# MCXN236 register map
Vendor: nxp.com; File version: 1.0
CPU: CM33 r2p0, little endian, MPU, FPU, VTOR, 3 interrupt priority bits
Registers are 32-bit, read-write, reset 0x0 unless marked. A register's access mark holds for its fields unless they carry their own. Offsets are from the block's base; [hi:lo] are bit positions; {n}, {i} and the like mark numbered series; 'fields as' and 'values as' point back to an identical list.

## SYSCON0 — SYSCON
Base 0x40000000
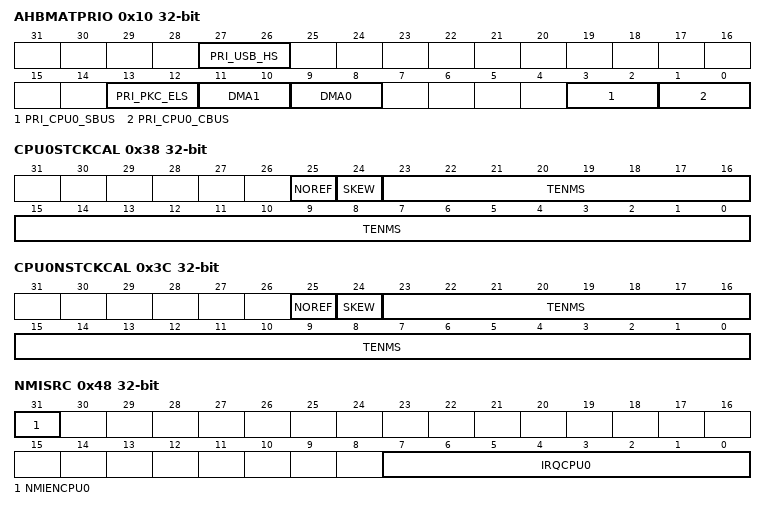
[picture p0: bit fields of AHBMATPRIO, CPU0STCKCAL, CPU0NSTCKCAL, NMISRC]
0x10 AHBMATPRIO — AHB Matrix Priority Control
  [all] fields
    {v}=LEVEL{v} (v=0..3)
  [27:26] PRI_USB_HS — USB-HS bus master priority level
  [13:12] PRI_PKC_ELS — PKC and ELS bus master priority level
  [11:10] DMA1 — DMA1 controller bus master priority level
  [9:8] DMA0 — DMA0 controller bus master priority level
  [3:2] PRI_CPU0_SBUS — CPU0 S-AHB bus master priority level
  [1:0] PRI_CPU0_CBUS — CPU0 C-AHB bus master priority level
0x38 CPU0STCKCAL — Secure CPU0 System Tick Calibration
  [25] NOREF — Whether the device provides a reference clock to the processor.
    0=YES_REF (Reference clock is provided); 1=NO_REF (No reference clock is provided)
  [24] SKEW — Whether the TENMS value is exact.
    0=EXACT (TENMS value is exact); 1=INEXACT (TENMS value is not exact or not given)
  [23:0] TENMS — Reload value for 10 ms (100 Hz) timing, subject to system clock skew errors. If the value reads as zero, the calibration value is not known.
0x3C CPU0NSTCKCAL — Non-Secure CPU0 System Tick Calibration
  [25] NOREF — Indicates whether the device provides a reference clock to the processor.
    values as CPU0STCKCAL.NOREF
  [24] SKEW — Indicates whether the TENMS value is exact.
    values as CPU0STCKCAL.SKEW
  [23:0] TENMS — Reload value for 10 ms (100 Hz) timing, subject to system clock skew errors. If the value reads as zero, the calibration value is not known.
0x48 NMISRC — NMI Source Select
  [31] NMIENCPU0 — Enables the Non-Maskable Interrupt (NMI) source selected by IRQCPU0.
    0=DISABLE; 1=ENABLE
  [7:0] IRQCPU0 — The IRQ number of the interrupt that acts as the Non-Maskable Interrupt (NMI) for CPU0, if enabled by NMIENCPU0.
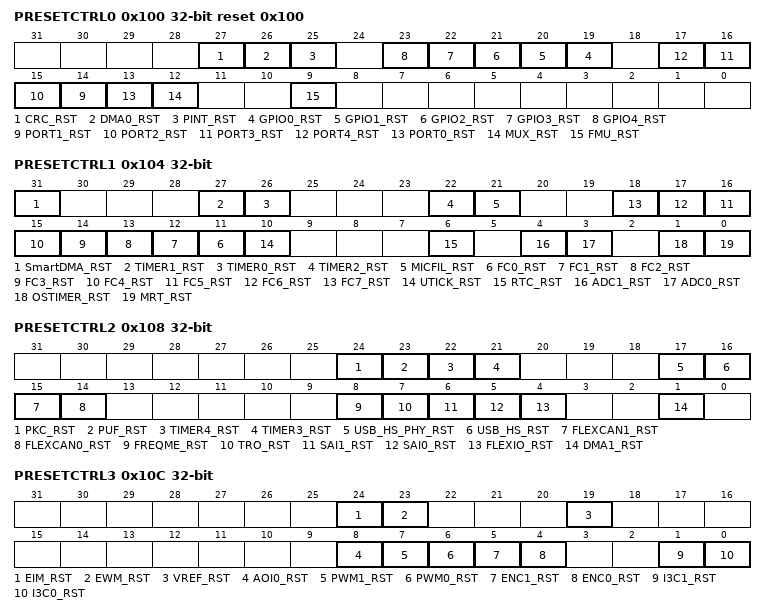
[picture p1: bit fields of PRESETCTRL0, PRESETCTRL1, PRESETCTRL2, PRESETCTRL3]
0x100 PRESETCTRL0 reset 0x100 (reset mask 0xCEFB13FC) — Peripheral Reset Control 0
  [all] fields
    0=RELEASED (Block is not reset); 1=ASSERTED (Block is reset)
  [27] CRC_RST — CRC reset control
  [26] DMA0_RST — DMA0 reset control
  [25] PINT_RST — PINT reset control
  [n+19] GPIO{n}_RST (n=0..4) — GPIO{n} reset control
  [n+13] PORT{n}_RST (n=1..4) — PORT{n} reset control
  [13] PORT0_RST — PORT0 controller reset control
  [12] MUX_RST — INPUTMUX reset control
  [9] FMU_RST — Flash management unit reset control
0x104 PRESETCTRL1 (reset mask 0xAFFFFF3F) — Peripheral Reset Control 1
  [all] fields
    0=RELEASED (Block is not reset); 1=ASSERTED (Block is reset)
  [31] SmartDMA_RST — SmartDMA reset control
  [27] TIMER1_RST — CTIMER1 reset control
  [26] TIMER0_RST — CTIMER0 reset control
  [22] TIMER2_RST — CTIMER2 reset control
  [21] MICFIL_RST — MICFIL reset control
  [n+11] FC{n}_RST (n=0..7) — LP_FLEXCOMM{n} reset control
  [10] UTICK_RST — UTICK reset control
  [6] RTC_RST — RTC reset control
  [4] ADC1_RST — ADC1 reset control
  [3] ADC0_RST — ADC0 reset control
  [1] OSTIMER_RST — OS Event Timer reset control
  [0] MRT_RST — MRT reset control
0x108 PRESETCTRL2 — Peripheral Reset Control 2
  [all] fields
    0=RELEASED (Block is not reset); 1=ASSERTED (Block is reset)
  [24] PKC_RST — PKC reset control
  [23] PUF_RST — PUF reset control
  [22] TIMER4_RST — CTIMER4 reset control
  [21] TIMER3_RST — CTIMER3 reset control
  [17] USB_HS_PHY_RST — USB HS PHY reset control
  [16] USB_HS_RST — USB HS reset control
  [15] FLEXCAN1_RST — CAN1 reset control
  [14] FLEXCAN0_RST — CAN0 reset control
  [8] FREQME_RST — FREQME reset control
  [7] TRO_RST — TRO reset control
  [6] SAI1_RST — SAI1 reset control
  [5] SAI0_RST — SAI0 reset control
  [4] FLEXIO_RST — FLEXIO reset control
  [1] DMA1_RST — DMA1 reset control
0x10C PRESETCTRL3 — Peripheral Reset Control 3
  [all] fields
    0=RELEASED (Block is not reset); 1=ASSERTED (Block is reset)
  [24] EIM_RST — EIM reset control
  [23] EWM_RST — EWM reset control
  [19] VREF_RST — VREF reset control
  [8] AOI0_RST — AOI0 reset control
  [7] PWM1_RST — PWM1 reset control
  [6] PWM0_RST — PWM0 reset control
  [5] ENC1_RST — ENC1 reset control
  [4] ENC0_RST — ENC0 reset control
  [1] I3C1_RST — I3C1 reset control
  [0] I3C0_RST — I3C0 reset control
{0x120+4i} PRESETCTRLSET[{i}] (i=0..3) wo — Peripheral Reset Control Set
  [31:0] DATA — Data array value, refer to corresponding position in PRESETCTRLn.
{0x140+4i} PRESETCTRLCLR[{i}] (i=0..3) wo — Peripheral Reset Control Clear
  fields as PRESETCTRLSET[0]
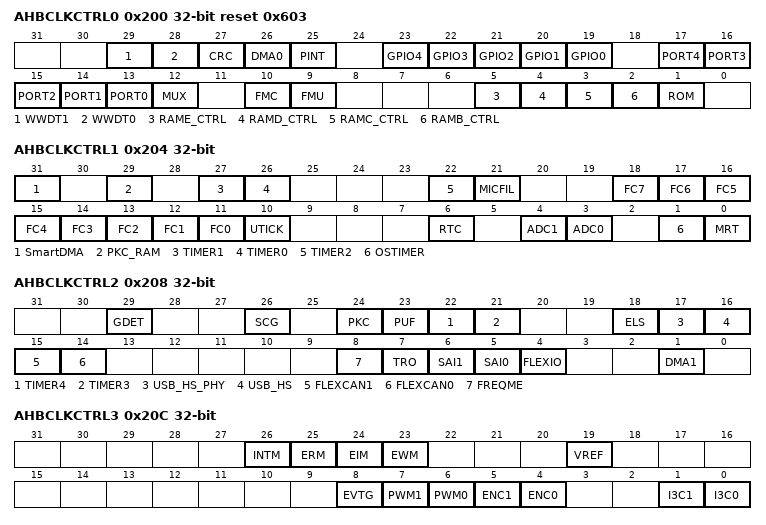
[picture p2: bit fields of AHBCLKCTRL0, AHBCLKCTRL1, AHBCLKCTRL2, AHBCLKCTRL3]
0x200 AHBCLKCTRL0 reset 0x603 — AHB Clock Control 0
  [all] fields
    0=DISABLE (Disables clock); 1=ENABLE (Enables clock)
  [29] WWDT1 — Enables the clock for WWDT1
  [28] WWDT0 — Enables the clock for WWDT0
  [27] CRC — Enables the clock for CRC
  [26] DMA0 — Enables the clock for DMA0
  [25] PINT — Enables the clock for PINT
  [n+19] GPIO{n} (n=0..4) — Enables the clock for GPIO{n}
  [n+13] PORT{n} (n=1..4) — Enables the clock for PORT{n}
  [13] PORT0 — Enables the clock for PORT0 controller
  [12] MUX — Enables the clock for INPUTMUX
  [10] FMC — Enables the clock for the Flash Memory Controller
  [9] FMU — Enables the clock for the Flash Management Unit
  [5] RAME_CTRL — Enables the clock for the RAME Controller
  [4] RAMD_CTRL — Enables the clock for the RAMD Controller
  [3] RAMC_CTRL — Enables the clock for the RAMC Controller
  [2] RAMB_CTRL — Enables the clock for the RAMB Controller
  [1] ROM — Enables the clock for the ROM
0x204 AHBCLKCTRL1 — AHB Clock Control 1
  [all] fields
    0=DISABLE (Disables clock); 1=ENABLE (Enables clock)
  [31] SmartDMA — Enables the clock for SmartDMA
  [29] PKC_RAM — Enables the clock for PKC RAM
  [27] TIMER1 — Enables the clock for CTIMER1
  [26] TIMER0 — Enables the clock for CTIMER0
  [22] TIMER2 — Enables the clock for CTIMER2
  [21] MICFIL — Enables the clock for MICFIL
  [n+11] FC{n} (n=0..7) — Enables the clock for LP_FLEXCOMM{n}
  [10] UTICK — Enables the clock for UTICK
  [6] RTC — Enables the clock for RTC
  [4] ADC1 — Enables the clock for ADC1
  [3] ADC0 — Enables the clock for ADC0
  [1] OSTIMER — Enables the clock for the OS Event Timer
  [0] MRT — Enables the clock for MRT
0x208 AHBCLKCTRL2 — AHB Clock Control 2
  [29] GDET — Enables the clock for GDET0 and GDET1
    0=DISABLE (Disables clock); 1=ENABLE (Enables clock)
  [26] SCG — Enables the clock for SCG
    0=DISABLE (Disables clock); 1=ENABLE (Enables clock)
  [24] PKC — Enables the clock for PKC
    0=DISABLE (Disables clock); 1=ENABLE (Enables clock)
  [23] PUF — Enables the clock for PUF
    0=DISABLE (Disables clock); 1=ENABLE (Enables clock)
  [22] TIMER4 — Enables the clock for CTIMER4
    0=DISABLE (Disables clock); 1=ENABLE (Enables clock)
  [21] TIMER3 — Enables the clock for CTIMER3
    0=DISABLE (Disables clock); 1=ENABLE (Enables clock)
  [18] ELS — Enables the clock for ELS
    0=DISABLE (Disables clock); 1=ENABLE (Enables clock)
  [17] USB_HS_PHY — Enables the clock for USB HS PHY
    0=DISABLE (Disables clock); 1=ENABLE (Enables clock)
  [16] USB_HS — Enables the clock for USB HS
    0=DISABLE (Disables clock); 1=ENABLE (Enables clock)
  [15] FLEXCAN1 — Enables the clock for FLEXCAN1
    0=DISABLE (Disables clock); 1=ENABLE (Enables clock)
  [14] FLEXCAN0 — Enables the clock for FLEXCAN0
    0=DISABLE (Disables clock); 1=ENABLE (Enables clock)
  [8] FREQME — Enables the clock for the Frequency meter
    0=DISABLE (Disables clock); 1=ENABLE (Enables clock)
  [7] TRO — Enables the clock for TRO
    0=DISABLE (Disables clock); 1=ENABLE (Enables clock)
  [6] SAI1 — Enables the clock for SAI1
    0=DISABLE (Disables clock); 1=ENABLE (Enables clock)
  [5] SAI0 — Enables the clock for SAI0
    0=DISABLE (Disables clock); 1=ENABLE (Enables clock)
  [4] FLEXIO — Enables the clock for Flexio
    0=DISABLE (Disables clock); 1=ENABLE (Enable clock)
  [1] DMA1 — Enables the clock for DMA1
    0=DISABLE (Disables clock); 1=ENABLE (Enables clock)
0x20C AHBCLKCTRL3 — AHB Clock Control 3
  [all] fields
    0=DISABLE (Disables clock); 1=ENABLE (Enables clock)
  [26] INTM — Enables the clock for INTM
  [25] ERM — Enables the clock for ERM
  [24] EIM — Enables the clock for EIM
  [23] EWM — Enables the clock for EWM
  [19] VREF — Enables the clock for VREF
  [8] EVTG — Enables the clock for EVTG
  [7] PWM1 — Enables the clock for PWM1
  [6] PWM0 — Enables the clock for PWM0
  [5] ENC1 — Enables the clock for ENC1
  [4] ENC0 — Enables the clock for ENC0
  [1] I3C1 — Enables the clock for I3C1
  [0] I3C0 — Enables the clock for I3C0
{0x220+4i} AHBCLKCTRLSET[{i}] (i=0..3) wo — AHB Clock Control Set
  [31:0] DATA — Data array value
{0x240+4i} AHBCLKCTRLCLR[{i}] (i=0..3) wo — AHB Clock Control Clear
  [31:0] DATA — Data array value
0x260 SYSTICKCLKSEL0 reset 0x7 — CPU0 System Tick Timer Source Select
  [2:0] SEL — Selects the System Tick Timer for CPU0 source
    0=ENUM_0x0 (SYSTICKCLKDIV0 output); 1=ENUM_0x1 (Clk 1 MHz clock); 2=ENUM_0x2 (LP Oscillator clock); {v}=ENUM_{0x0+v} (No clock) (v=3..7)
0x268 TRACECLKSEL reset 0x7 — Trace Clock Source Select
  [2:0] SEL — Selects the trace clock source.
    0=ENUM_0x0 (TRACECLKDIV output); 1=ENUM_0x1 (Clk 1 MHz clock); 2=ENUM_0x2 (LP Oscillator clock); {v}=ENUM_{0x0+v} (No clock) (v=3..7)
{0x26C+4i} CTIMERCLKSEL[{i}] (i=0..4) reset 0xF — CTIMER Clock Source Select
  [3:0] SEL — Selects the CTIMER clock source.
    0=ENUM_0x0 (FRO_1M clock); 1=ENUM_0x1 (PLL0 clock); 2=ENUM_0x2 (PLL1_clk0 clock); 3=ENUM_0x3 (FRO_HF clock); 4=ENUM_0x4 (FRO 12MHz clock); 5=ENUM_0x5 (SAI0 MCLK IN clock); 6=ENUM_0x6 (LP Oscillator clock); 7=ENUM_0x7 (No clock); 8=ENUM_0x8 (SAI1 MCLK IN clock); 9=ENUM_0x9 (SAI0 TX_BCLK clock); 10=ENUM_0xA (SAI0 RX_BCLK clock); 11=ENUM_0xB (SAI1 TX_BCLK clock); 12=ENUM_0xC (SAI1 RX_BCLK clock); 13=ENUM_0xD (No clock); 14=ENUM_0xE (No clock); 15=ENUM_0xF (No clock)
0x288 CLKOUTSEL reset 0xF — CLKOUT Clock Source Select
  [3:0] SEL — Selects the CLKOUT clock source.
    0=ENUM_0x0 (Main clock (main_clk)); 1=ENUM_0x1 (PLL0 clock (pll0_clk)); 2=ENUM_0x2 (CLKIN clock (clk_in)); 3=ENUM_0x3 (FRO_HF clock (fro_hf)); 4=ENUM_0x4 (FRO 12 MHz clock (fro_12m)); 5=ENUM_0x5 (PLL1_clk0 clock (pll1_clk)); 6=ENUM_0x6 (LP Oscillator clock (lp_osc)); 7=ENUM_0x7 (USB PLL clock (usb_pll_clk)); {v}=ENUM_{0x0+v} (No clock) (v=8..15)
0x2A4 ADC0CLKSEL reset 0x7 — ADC0 Clock Source Select
  [2:0] SEL — Selects the ADC0 clock source.
    0=ENUM_0x0 (No clock); 1=ENUM_0x1 (PLL0 clock); 2=ENUM_0x2 (FRO_HF clock); 3=ENUM_0x3 (FRO 12 MHz clock); 4=ENUM_0x4 (Clk_in); 5=ENUM_0x5 (PLL1_clk0 clock); 6=ENUM_0x6 (USB PLL clock); 7=ENUM_0x7 (No clock)
{0x2B0+4i} FCCLKSEL[{i}] (i=0..7) reset 0x7 — LP_FLEXCOMM Clock Source Select for Fractional Rate Divider
  [2:0] SEL — Selects the LP_FLEXCOMM clock source for Fractional Rate Divider.
    0=ENUM_0x0 (No clock); 1=ENUM_0x1 (PLL divided clock); 2=ENUM_0x2 (FRO 12 MHz clock); 3=ENUM_0x3 (fro_hf_div clock); 4=ENUM_0x4 (CLK_1MHz clock); 5=ENUM_0x5 (USB PLL clock); 6=ENUM_0x6 (LP Oscillator clock); 7=ENUM_0x7 (No clock)
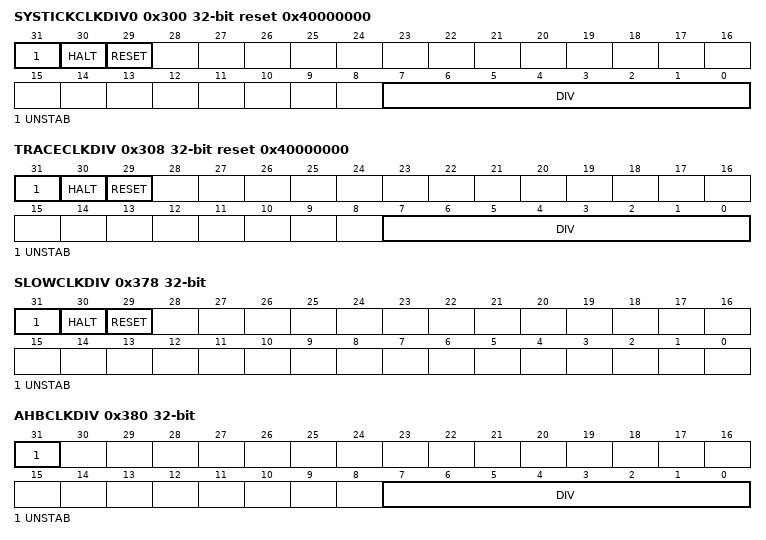
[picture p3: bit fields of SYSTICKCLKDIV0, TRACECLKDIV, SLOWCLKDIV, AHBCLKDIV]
0x300 SYSTICKCLKDIV0 reset 0x40000000 — CPU0 System Tick Timer Divider
  [31] UNSTAB ro — Divider status flag
    0=STABLE (Divider clock is stable); 1=ONGOING (Clock frequency is not stable)
  [30] HALT — Halts the divider counter
    0=RUN (Divider clock is running); 1=HALT (Divider clock is stopped)
  [29] RESET — Resets the divider counter
    0=RELEASED (Divider is not reset); 1=ASSERTED (Divider is reset.)
  [7:0] DIV — Clock divider value
0x308 TRACECLKDIV reset 0x40000000 — TRACE Clock Divider
  [31] UNSTAB ro — Divider status flag
    values as SYSTICKCLKDIV0.UNSTAB
  [30] HALT — Halts the divider counter
    values as SYSTICKCLKDIV0.HALT
  [29] RESET — Resets the divider counter
    0=RELEASED (Divider is not reset); 1=ASSERTED (Divider is reset)
  [7:0] DIV — Clock divider value
0x378 SLOWCLKDIV — SLOW_CLK Clock Divider
  [31] UNSTAB ro — Divider status flag
    values as SYSTICKCLKDIV0.UNSTAB
  [30] HALT — Halts the divider counter
    values as SYSTICKCLKDIV0.HALT
  [29] RESET — Resets the divider counter
    values as TRACECLKDIV.RESET
0x380 AHBCLKDIV — System Clock Divider
  [31] UNSTAB ro — Divider status flag
    values as SYSTICKCLKDIV0.UNSTAB
  [7:0] DIV — Clock divider value
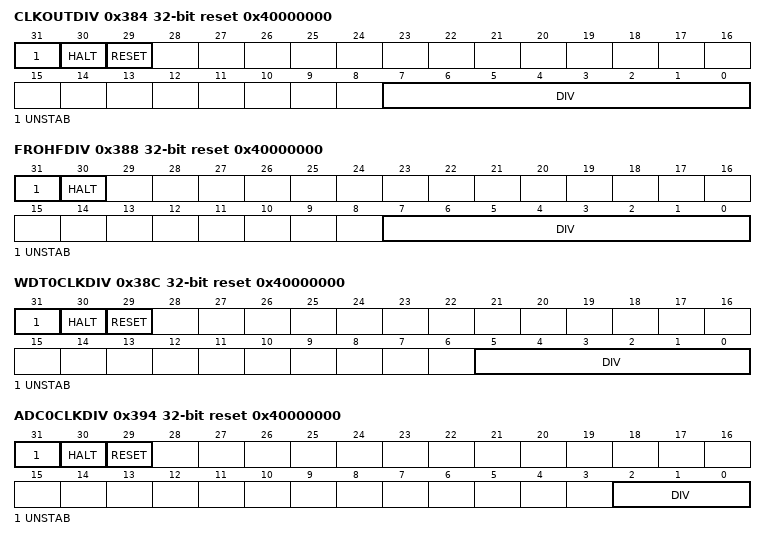
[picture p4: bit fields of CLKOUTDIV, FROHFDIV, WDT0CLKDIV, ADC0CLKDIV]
0x384 CLKOUTDIV reset 0x40000000 — CLKOUT Clock Divider
  fields as TRACECLKDIV
0x388 FROHFDIV reset 0x40000000 — FRO_HF_DIV Clock Divider
  [31] UNSTAB ro — Divider status flag
    values as SYSTICKCLKDIV0.UNSTAB
  [30] HALT ro — Halts the divider counter
    0=RUN (Divider clock is running, this bit is set to 0 when the register is written.); 1=HALT (Divider clock is stopped)
  [7:0] DIV — Clock divider value
0x38C WDT0CLKDIV reset 0x40000000 — WDT0 Clock Divider
  [31] UNSTAB ro — Divider status flag
    values as SYSTICKCLKDIV0.UNSTAB
  [30] HALT — Halts the divider counter
    values as SYSTICKCLKDIV0.HALT
  [29] RESET — Resets the divider counter
    values as TRACECLKDIV.RESET
  [5:0] DIV — Clock divider value
0x394 ADC0CLKDIV reset 0x40000000 — ADC0 Clock Divider
  [31] UNSTAB ro — Divider status flag
    values as SYSTICKCLKDIV0.UNSTAB
  [30] HALT — Halts the divider counter
    values as SYSTICKCLKDIV0.HALT
  [29] RESET — Resets the divider counter
    values as TRACECLKDIV.RESET
  [2:0] DIV — Clock divider value
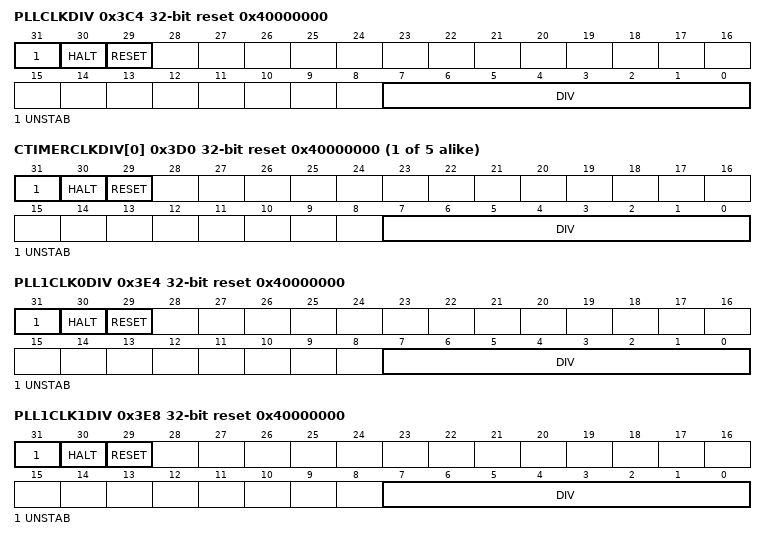
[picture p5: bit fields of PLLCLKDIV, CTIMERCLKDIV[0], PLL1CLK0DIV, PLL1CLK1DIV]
0x3C4 PLLCLKDIV reset 0x40000000 — PLL Clock Divider
  fields as TRACECLKDIV
{0x3D0+4i} CTIMERCLKDIV[{i}] (i=0..4) reset 0x40000000 — CTimer Clock Divider
  [31] UNSTAB — Divider status flag
    0=ENABLE (Stable divider clock); 1=DISABLE (Unstable clock frequency)
  [30] HALT — Halts the divider counter
    0=ENABLE (Divider clock is running); 1=DISABLE (Divider clock has stopped)
  [29] RESET — Resets the divider counter
    0=DISABLE (Divider is not reset); 1=ENABLE (Divider is reset)
  [7:0] DIV — Clock divider value
0x3E4 PLL1CLK0DIV reset 0x40000000 — PLL1 Clock 0 Divider
  fields as TRACECLKDIV
0x3E8 PLL1CLK1DIV reset 0x40000000 — PLL1 Clock 1 Divider
  fields as TRACECLKDIV
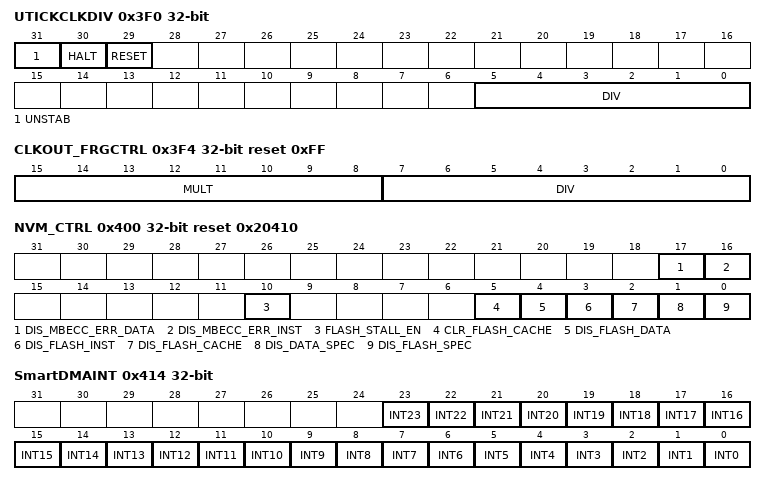
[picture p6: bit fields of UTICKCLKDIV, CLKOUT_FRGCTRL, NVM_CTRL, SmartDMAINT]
0x3F0 UTICKCLKDIV — UTICK Clock Divider
  fields as WDT0CLKDIV
0x3F4 CLKOUT_FRGCTRL reset 0xFF — CLKOUT FRG Control
  [15:8] MULT — Numerator value
  [7:0] DIV — Divider value
0x3FC CLKUNLOCK — Clock Configuration Unlock
  [0] UNLOCK — Controls clock configuration registers access (for example, xxxDIV, xxxSEL)
    0=ENABLE (Updates are allowed to all clock configuration registers); 1=FREEZE (Freezes all clock configuration registers update)
0x400 NVM_CTRL reset 0x20410 — NVM Control
  [17] DIS_MBECC_ERR_DATA — Bus error on data multi-bit ECC error control
    0=ENABLE (Enables bus error on multi-bit ECC error for data); 1=DISABLE (Disables bus error on multi-bit ECC error for data)
  [16] DIS_MBECC_ERR_INST — Bus error on instruction multi-bit ECC error control
    0=ENABLE (Enables bus error on multi-bit ECC error for instruction); 1=DISABLE (Disables bus error on multi-bit ECC error for instruction)
  [10] FLASH_STALL_EN — FLASH stall on busy control
    0=ENABLE (No stall on FLASH busy); 1=DISABLE (Stall on FLASH busy)
  [5] CLR_FLASH_CACHE — Clear flash cache control
    0=ENABLE (No clear flash cache); 1=DISABLE (Clears flash cache)
  [4] DIS_FLASH_DATA — Flash data cache control
    0=ENABLE (Enables flash data cache when DIS_FLASH_CACHE=0); 1=DISABLE (Disables flash data cache)
  [3] DIS_FLASH_INST — Flash instruction cache control
    0=ENABLE (Enables flash instruction cache when DIS_FLASH_CACHE=0); 1=DISABLE (Disables flash instruction cache)
  [2] DIS_FLASH_CACHE — Flash cache control
    0=ENABLE (Enables flash cache); 1=DISABLE (Disables flash cache)
  [1] DIS_DATA_SPEC — Flash data speculation control
    0=ENABLE (Enables data speculation); 1=DISABLE (Disables data speculation)
  [0] DIS_FLASH_SPEC — Flash speculation control
    0=ENABLE (Enables flash speculation); 1=DISABLE (Disables flash speculation)
0x404 ROMCR — ROM Wait State
  [0] ROM_WAIT — ROM waiting Arm core and other masters for one cycle
    0=DISABLE (Disabled); 1=Enabled
0x414 SmartDMAINT — SmartDMA Interrupt Hijack
  [all] fields
    0=DISABLE; 1=ENABLE
  [23] INT23 — SmartDMA hijack NVIC IRQ77
  [22] INT22 — SmartDMA hijack NVIC IRQ67
  [21] INT21 — SmartDMA hijack NVIC IRQ66
  [20] INT20 — SmartDMA hijack NVIC IRQ51
  [19] INT19 — SmartDMA hijack NVIC IRQ50
  [18] INT18 — SmartDMA hijack NVIC IRQ47
  [17] INT17 — SmartDMA hijack NVIC IRQ45
  [n] INT{n} (n=3..16) — SmartDMA hijack NVIC IRQ{n+26}
  [2] INT2 — SmartDMA hijack NVIC IRQ18
  [1] INT1 — SmartDMA hijack NVIC IRQ17
  [0] INT0 — SmartDMA hijack NVIC IRQ1
0x464 ADC1CLKSEL reset 0x7 — ADC1 Clock Source Select
  [2:0] SEL — Selects the ADC1 clock source
    0=ENUM_0x0 (No clock); 1=ENUM_0x1 (PLL0 clock); 2=ENUM_0x2 (FRO_HF clock); 3=ENUM_0x3 (FRO 12 MHz clock); 4=ENUM_0x4 (Clk_in clock); 5=ENUM_0x5 (PLL1_clk0 clock); 6=ENUM_0x6 (USB PLL clock); 7=ENUM_0x7 (No clock)
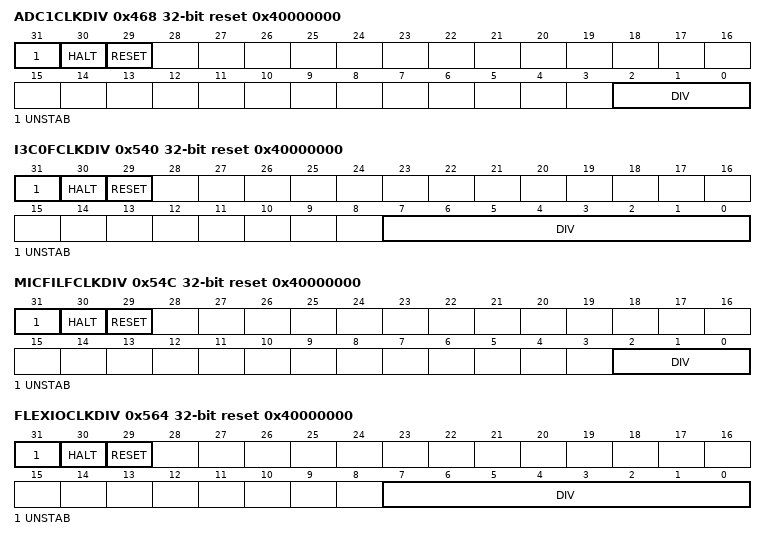
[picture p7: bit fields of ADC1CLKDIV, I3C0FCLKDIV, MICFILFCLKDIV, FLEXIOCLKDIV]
0x468 ADC1CLKDIV reset 0x40000000 — ADC1 Clock Divider
  fields as ADC0CLKDIV
0x470 RAM_INTERLEAVE — Control PKC RAM Interleave Access
  [0] INTERLEAVE — Controls PKC RAM access for PKC RAM 0 and PKC RAM 1
    0=NORMAL (RAM access to PKC RAM 0 and PKC RAM 1 is consecutive.); 1=INTERLEAVE (RAM access to PKC RAM 0 and PKC RAM 1 is interleaved. This setting is need for PKC L0 memory access.)
0x52C PLLCLKDIVSEL reset 0x7 — PLL Clock Divider Clock Selection
  [2:0] SEL — Selects the PLL Clock Divider source clock
    0=PLL0 clock; 1=pll1_clk0; {v}=No clock (v=2..7)
0x530 I3C0FCLKSEL reset 0x7 — I3C0 Functional Clock Selection
  [2:0] SEL — Selects the I3C0 clock
    0=No clock; 1=PLL0 clock; 2=CLKIN clock; 3=FRO_HF clock; 4=No clock; 5=PLL1_clk0 clock; 6=USB PLL clock; 7=No clock
0x540 I3C0FCLKDIV reset 0x40000000 — I3C0 Functional Clock FCLK Divider
  fields as TRACECLKDIV
0x548 MICFILFCLKSEL reset 0xF — MICFIL Clock Selection
  [3:0] SEL — Selects the MICFIL clock
    0=FRO_12M clock; 1=PLL0 clock; 2=CLKIN clock; 3=FRO_HF clock; 4=PLL1_clk0 clock; 5=SAI0_MCLK clock; 6=USB PLL clock; 7=No clock; 8=SAI1_MCLK clock; {v}=No clock (v=9..15)
0x54C MICFILFCLKDIV reset 0x40000000 — MICFIL Clock Division
  fields as ADC0CLKDIV
0x560 FLEXIOCLKSEL reset 0x7 — FLEXIO Clock Selection
  [2:0] SEL — Selects the FLEXIO clock
    0=No clock; 1=PLL0 clock; 2=CLKIN clock; 3=FRO_HF clock; 4=FRO_12M clock; 5=PLL1_clk0 clock; 6=USB PLL clock; 7=No clock
0x564 FLEXIOCLKDIV reset 0x40000000 — FLEXIO Function Clock Divider
  fields as TRACECLKDIV
0x5A0 FLEXCAN0CLKSEL reset 0x7 — FLEXCAN0 Clock Selection
  [2:0] SEL — Selects the FLEXCAN0 clock
    values as I3C0FCLKSEL.SEL
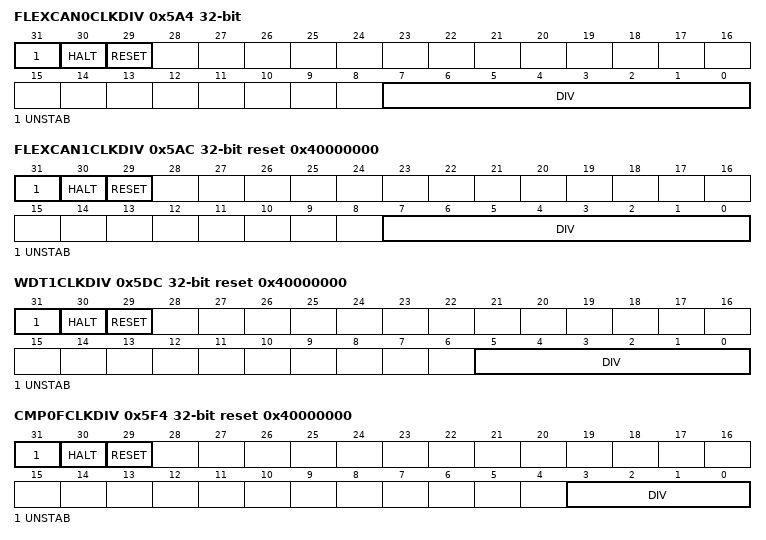
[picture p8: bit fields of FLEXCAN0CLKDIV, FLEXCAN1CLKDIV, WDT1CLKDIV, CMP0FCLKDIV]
0x5A4 FLEXCAN0CLKDIV — FLEXCAN0 Function Clock Divider
  fields as TRACECLKDIV
0x5A8 FLEXCAN1CLKSEL reset 0x7 — FLEXCAN1 Clock Selection
  [2:0] SEL — Selects the FLEXCAN1 clock
    values as I3C0FCLKSEL.SEL
0x5AC FLEXCAN1CLKDIV reset 0x40000000 — FLEXCAN1 Function Clock Divider
  fields as TRACECLKDIV
0x5D4 EWM0CLKSEL reset 0x1 — EWM0 Clock Selection
  [0] SEL — Selects the EWM0 clock
    0=clk_16k[2]; 1=xtal32k[2]
0x5D8 WDT1CLKSEL reset 0x3 — WDT1 Clock Selection
  [1:0] SEL — Selects the WDT1 clock
    0=FRO16K clock 2; 1=fro_hf_div clock; 2=clk_1m clock; 3=clk_1m clock
0x5DC WDT1CLKDIV reset 0x40000000 — WDT1 Function Clock Divider
  fields as WDT0CLKDIV
0x5E0 OSTIMERCLKSEL reset 0x3 — OSTIMER Clock Selection
  [1:0] SEL — Selects the OS Event Timer clock
    0=clk_16k[2]; 1=xtal32k[2]; 2=clk_1m clock; 3=No clock
0x5F0 CMP0FCLKSEL reset 0x7 — CMP0 Function Clock Selection
  [2:0] SEL — Selects the CMP0 function clock
    0=No clock; 1=PLL0 clock; 2=FRO_HF clock; 3=FRO_12M clock; 4=CLKIN clock; 5=PLL1_clk0 clock; 6=USB PLL clock; 7=No clock
0x5F4 CMP0FCLKDIV reset 0x40000000 — CMP0 Function Clock Divider
  [31] UNSTAB ro — Divider status flag
    values as SYSTICKCLKDIV0.UNSTAB
  [30] HALT — Halts the divider counter
    values as SYSTICKCLKDIV0.HALT
  [29] RESET — Resets the divider counter
    values as TRACECLKDIV.RESET
  [3:0] DIV — Clock divider value
0x5F8 CMP0RRCLKSEL reset 0x7 — CMP0 Round Robin Clock Selection
  [2:0] SEL — Selects the CMP0 round robin clock
    values as CMP0FCLKSEL.SEL
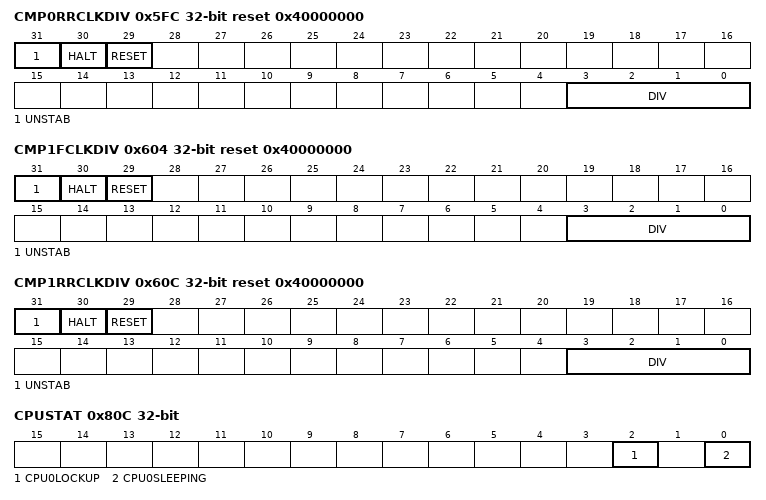
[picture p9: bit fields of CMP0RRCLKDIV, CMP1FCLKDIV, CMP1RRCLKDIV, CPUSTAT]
0x5FC CMP0RRCLKDIV reset 0x40000000 — CMP0 Round Robin Clock Divider
  fields as CMP0FCLKDIV
0x600 CMP1FCLKSEL reset 0x7 — CMP1 Function Clock Selection
  [2:0] SEL — Selects the CMP1 function clock
    values as CMP0FCLKSEL.SEL
0x604 CMP1FCLKDIV reset 0x40000000 — CMP1 Function Clock Divider
  fields as CMP0FCLKDIV
0x608 CMP1RRCLKSEL reset 0x7 — CMP1 Round Robin Clock Source Select
  [2:0] SEL — Selects the CMP1 round robin clock
    values as CMP0FCLKSEL.SEL
0x60C CMP1RRCLKDIV reset 0x40000000 — CMP1 Round Robin Clock Division
  fields as CMP0FCLKDIV
0x80C CPUSTAT ro — CPU Status
  [2] CPU0LOCKUP — CPU0 lockup state
    0=AWAKE (CPU is not in lockup); 1=SLEEPING (CPU is in lockup)
  [0] CPU0SLEEPING — CPU0 sleeping state
    0=AWAKE (CPU is not sleeping); 1=SLEEPING (CPU is sleeping)
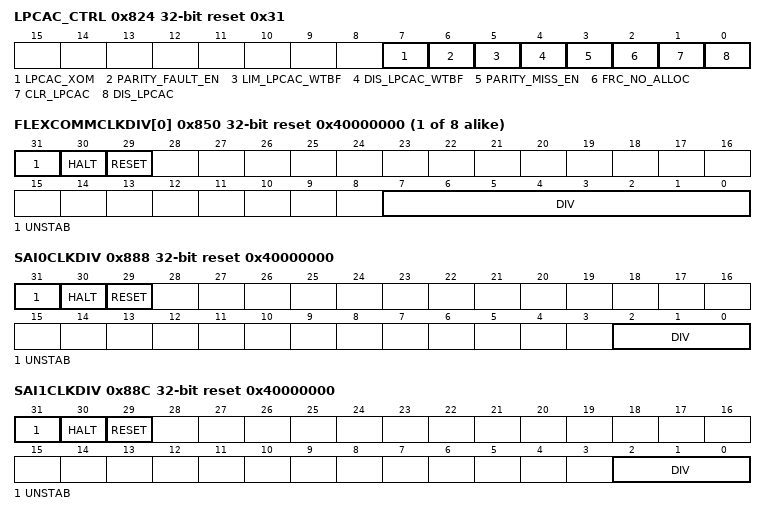
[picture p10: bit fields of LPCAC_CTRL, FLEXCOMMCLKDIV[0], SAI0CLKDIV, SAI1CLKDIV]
0x824 LPCAC_CTRL reset 0x31 — LPCAC Control
  [7] LPCAC_XOM — LPCAC XOM(eXecute-Only-Memory) attribute control
    0=DISABLE (Disabled.); 1=ENABLE (Enabled.)
  [6] PARITY_FAULT_EN — Enable parity error report.
    0=DISABLE (Disables parity error report); 1=ENABLE (Enables parity error report)
  [5] LIM_LPCAC_WTBF — Limit LPCAC Write Through Buffer.
    0=DISABLE (Write buffer enabled when transaction is bufferable.); 1=ENABLE (Write buffer enabled when transaction is cacheable and bufferable)
  [4] DIS_LPCAC_WTBF — Disable LPCAC Write Through Buffer.
    0=DISABLE (Enables write through buffer); 1=ENABLE (Disables write through buffer)
  [3] PARITY_MISS_EN — Enables parity miss.
    0=DISABLE (Disabled); 1=ENABLE (Enables parity, miss on parity error)
  [2] FRC_NO_ALLOC — Forces no allocation.
    0=ENABLE (Forces allocation); 1=DISABLE (Forces no allocation)
  [1] CLR_LPCAC — Clears the cache function.
    0=ENABLE (Unclears the cache); 1=DISABLE (Clears the cache)
  [0] DIS_LPCAC — Disables/enables the cache function.
    0=ENABLE (Enabled); 1=DISABLE (Disabled)
{0x850+4i} FLEXCOMMCLKDIV[{i}] (i=0..7) reset 0x40000000 — LP_FLEXCOMM Clock Divider
  fields as TRACECLKDIV
0x878 UTICKCLKSEL reset 0x2 — UTICK Function Clock Source Select
  [1:0] SEL — Selects the clock source
    0=clk_in; 1=xtal32k[2]; 2=clk_1m clock; 3=No clock
0x880 SAI0CLKSEL reset 0x7 — SAI0 Function Clock Source Select
  [2:0] SEL — Selects the clock source
    0=No clock; 1=PLL0 clock; 2=CLKIN clock; 3=FRO_HF clock; 4=PLL1_CLK0 clock; 5=No clock; 6=USB PLL clock; 7=No clock
0x884 SAI1CLKSEL reset 0x7 — SAI1 Function Clock Source Select
  fields as SAI0CLKSEL
0x888 SAI0CLKDIV reset 0x40000000 — SAI0 Function Clock Division
  fields as ADC0CLKDIV
0x88C SAI1CLKDIV reset 0x40000000 — SAI1 Function Clock Division
  fields as ADC0CLKDIV
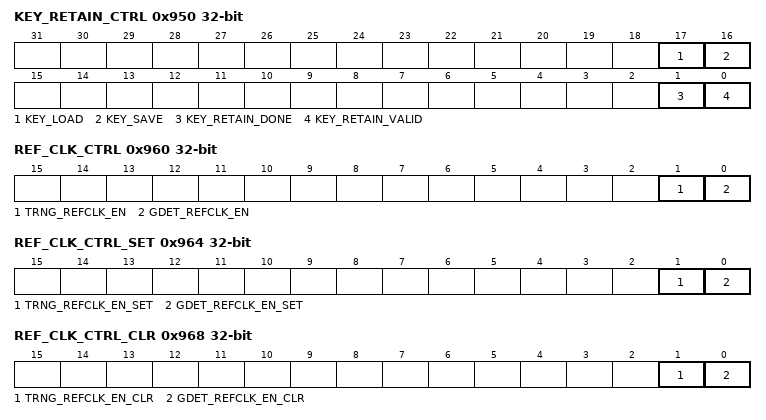
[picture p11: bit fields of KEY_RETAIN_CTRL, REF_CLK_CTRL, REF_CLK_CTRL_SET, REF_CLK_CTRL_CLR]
0x950 KEY_RETAIN_CTRL — Key Retain Control
  [17] KEY_LOAD — Do not set both KEY_SAVE and KEY_LOAD at the same time
    0=DISABLE (Key load sequence is disabled.); 1=ENABLE (Key load sequence is enabled.)
  [16] KEY_SAVE — Do not set both KEY_SAVE and KEY_LOAD at the same time
    0=DISABLE (Key save sequence is disabled.); 1=ENABLE (Key save sequence is enabled.)
  [1] KEY_RETAIN_DONE ro — Indicates the successful completion of the key_save or key_load routine. Once set, to clear the key_retain_done flag, both key_save and key_load should be cleared by software.
    0=NOT_DONE (Key save / load sequence has not completed.); 1=DONE (Key save / load sequence has completed.)
  [0] KEY_RETAIN_VALID ro — Indicates if the PUF key has been retained in the VBAT domain and has not been reset or otherwise invalidated by software.
    0=NOT_VALID (PUF key is not retained in VBAT domain.); 1=VALID (PUF key is retained in VBAT domain.)
0x960 REF_CLK_CTRL — FRO 48MHz Reference Clock Control
  [1] TRNG_REFCLK_EN — ELS TRNG reference clock enable bit
    0=DISABLE (Disabled.); 1=ENABLE (Enabled)
  [0] GDET_REFCLK_EN — GDET reference clock enable bit
    0=DISABLE (Disabled.); 1=ENABLE (Enabled)
0x964 REF_CLK_CTRL_SET wo — FRO 48MHz Reference Clock Control Set
  [1] TRNG_REFCLK_EN_SET — ELS TRNG reference clock enable set bit
    0=DISABLE (No effect.); 1=ENABLE (Set to 1)
  [0] GDET_REFCLK_EN_SET — GDET reference clock enable set bit
    0=DISABLE (No effect.); 1=ENABLE (Set to 1)
0x968 REF_CLK_CTRL_CLR wo — FRO 48MHz Reference Clock Control Clear
  [1] TRNG_REFCLK_EN_CLR — ELS TRNG reference clock enable clear bit
    0=DISABLE (No effect.); 1=ENABLE (Set to 0)
  [0] GDET_REFCLK_EN_CLR — GDET reference clock enable clear bit
    0=DISABLE (No effect.); 1=ENABLE (Set to 0)
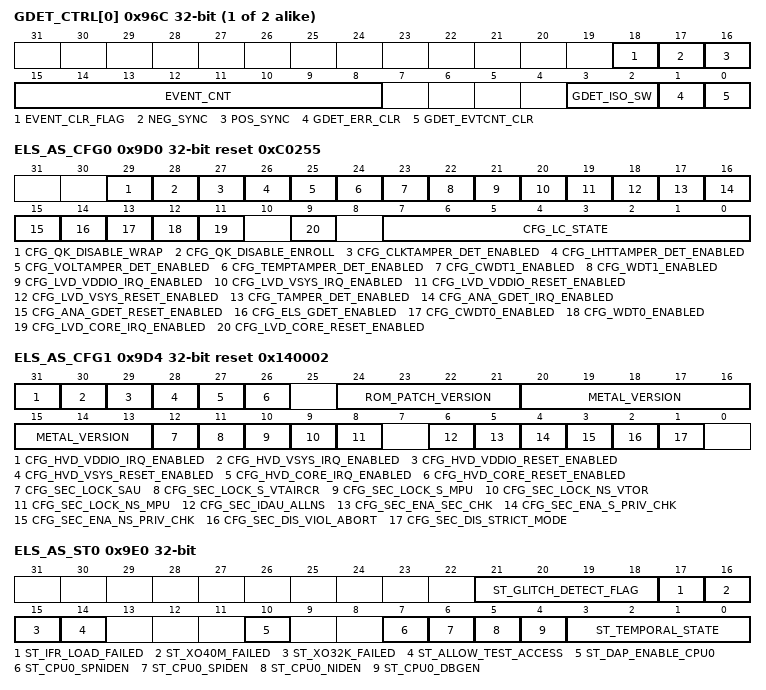
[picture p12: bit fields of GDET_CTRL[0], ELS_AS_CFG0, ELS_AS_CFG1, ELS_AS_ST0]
{0x96C+4i} GDET_CTRL[{i}] (i=0..1) — GDET Control Register
  [18] EVENT_CLR_FLAG ro — Event counter cleared
    0=DISABLE (Event counter not cleared); 1=ENABLE (Event counter cleared)
  [17] NEG_SYNC ro — Negative glitch detected
    0=DISABLE (Negative glitch not detected); 1=ENABLE (Negative glitch detected)
  [16] POS_SYNC ro — Positive glitch detected
    0=DISABLE (Positive glitch not detected); 1=ENABLE (Positive glitch detected)
  [15:8] EVENT_CNT ro — Event count value
  [3:2] GDET_ISO_SW — GDET isolation control
    0=DISABLE0 (Isolation is disabled); 1=DISABLE1 (Isolation is disabled); 2=ENABLE (Isolation is enabled. When both GDET0_CTRL/GDET1_CTRL GDET_ISO_SW are "10", isolation_on is asserted.); 3=DISABLE3 (Isolation is disabled)
  [1] GDET_ERR_CLR — Clears GDET error status
    0=DISABLE (Error status not cleared); 1=ENABLE (Clears error status)
  [0] GDET_EVTCNT_CLR — Controls the GDET clean event counter
    0=DISABLE (Event counter not cleared); 1=ENABLE (Clears event counter)
0x980 ELS_OTP_LC_STATE ro reset 0x55 — Life Cycle State Register
  [7:0] OTP_LC_STATE — OTP life cycle state
0x984 ELS_OTP_LC_STATE_DP ro reset 0x55 — Life Cycle State Register (Duplicate)
  [7:0] OTP_LC_STATE_DP — OTP life cycle state
0x988 ELS_TEMPORAL_STATE
  [3:0] TEMPORAL_STATE
0x98C ELS_KDF_MASK — Key Derivation Function Mask
  [31:0] KDF_MASK — Key derivation function mask
0x9D0 ELS_AS_CFG0 ro reset 0xC0255 — ELS AS Configuration
  [29] CFG_QK_DISABLE_WRAP — When QK PUF "qk_disable_wrap" input is driven 1, this bit indicates state 1
  [28] CFG_QK_DISABLE_ENROLL — When QK PUF "qk_disable_enroll" input is driven 1, this bit indicates state 1
  [27] CFG_CLKTAMPER_DET_ENABLED — When clk tamper detector is enabled in VBAT, this bit indicates state 1.
  [26] CFG_LHTTAMPER_DET_ENABLED — When light tamper detector is enabled in VBAT, this bit indicates state 1.
  [25] CFG_VOLTAMPER_DET_ENABLED — When voltage tamper detector is enabled in VBAT, this bit indicates state 1.
  [24] CFG_TEMPTAMPER_DET_ENABLED — When temperature tamper detector is enabled in VBAT, this bit indicates state 1.
  [23] CFG_CWDT1_ENABLED — When Code WatchDog Timer 1 is activated, this bit indicates state 1.
  [22] CFG_WDT1_ENABLED — When WatchDog Timer 1 is activated, this bit indicates state 1.
  [21] CFG_LVD_VDDIO_IRQ_ENABLED — When SPC VDDIO LVD analog detector are turned on and VDDIO LVD irq are enabled, this bit indicates state 1.
  [20] CFG_LVD_VSYS_IRQ_ENABLED — When SPC VSYS LVD analog detector are turned on and VSYS LVD irq are enabled, this bit indicates state 1.
  [19] CFG_LVD_VDDIO_RESET_ENABLED — When SPC VDDIO LVD analog detector are turned on and VDDIO LVD reset are enabled, this bit indicates state 1.
  [18] CFG_LVD_VSYS_RESET_ENABLED — When SPC VSYS LVD analog detector are turned on and VSYS LVD reset are enabled, this bit indicates state 1.
  [17] CFG_TAMPER_DET_ENABLED — When tamper detector is enabled in TDET, this bit indicates state 1.
  [16] CFG_ANA_GDET_IRQ_ENABLED — When SPC analog glitch detect IRQ is enabled, this bit indicates state 1
  [15] CFG_ANA_GDET_RESET_ENABLED — When SPC analog glitch detect reset is enabled, this bit indicates state 1
  [14] CFG_ELS_GDET_ENABLED — When either GDET is enabled, this bit indicates state 1.
  [13] CFG_CWDT0_ENABLED — When Code WatchDog Timer 0 is activated, this bit indicates state 1
  [12] CFG_WDT0_ENABLED — When WatchDog Timer 0 is activated, this bit indicates state 1
  [11] CFG_LVD_CORE_IRQ_ENABLED — When SPC CORE LVD analog detector are turned on, and CORE LVD IRQ are enabled, this bit indicates state 1.
  [9] CFG_LVD_CORE_RESET_ENABLED — When SPC CORE LVD analog detector are turned on, and CORE LVD reset are enabled, this bit indicates state 1.
  [7:0] CFG_LC_STATE — LC state configuration bit
0x9D4 ELS_AS_CFG1 ro reset 0x140002 — ELS AS Configuration1
  [31] CFG_HVD_VDDIO_IRQ_ENABLED — When SPC VDDIO HVD analog detector are turned on and VDDIO HVD irq are enabled, this bit indicates state 1.
  [30] CFG_HVD_VSYS_IRQ_ENABLED — When SPC VSYS HVD analog detector are turned on and VSYS HVD irq are enabled, this bit indicates state 1.
  [29] CFG_HVD_VDDIO_RESET_ENABLED — When SPC VDDIO HVD analog detector are turned on and VDDIO HVD reset are enabled, this bit indicates state 1.
  [28] CFG_HVD_VSYS_RESET_ENABLED — When SPC VSYS HVD analog detector are turned on and VSYS HVD reset are enabled, this bit indicates state 1.
  [27] CFG_HVD_CORE_IRQ_ENABLED — When SPC CORE HVD analog detector are turned on, and CORE HVD IRQ are enabled, this bit indicates state 1.
  [26] CFG_HVD_CORE_RESET_ENABLED — When SPC CORE HVD analog detector are turned on, and CORE HVD reset are enabled, this bit indicates state 1.
  [24:21] ROM_PATCH_VERSION
  [20:13] METAL_VERSION
  [12] CFG_SEC_LOCK_SAU — When the LOCK_SAU bits in CPU0_LOCK_REG on the AHB secure controller are not equal to 10, this bit indicates state 1
  [11] CFG_SEC_LOCK_S_VTAIRCR — When the LOCK_S_VTAIRCR bits in CPU0_LOCK_REG on the AHB secure controller are not equal to 10, this bit indicates state 1
  [10] CFG_SEC_LOCK_S_MPU — When the LOCK_S_MPU bits in CPU0_LOCK_REG on the AHB secure controller are not equal to 10, this bit indicates state 1
  [9] CFG_SEC_LOCK_NS_VTOR — When the LOCK_NS_VTOR bits in CPU0_LOCK_REG on the AHB secure controller are not equal to 10, this bit indicates state 1
  [8] CFG_SEC_LOCK_NS_MPU — When the LOCK_NS_MPU bits in CPU0_LOCK_REG on the AHB secure controller are not equal to 10, this bit indicates state 1
  [6] CFG_SEC_IDAU_ALLNS — When the IDAU_ALL_NS bits in MISC_CTRL_REG and MISC_CTRL_DP_REG on the AHB secure controller are equal to 01, this bit indicates state 1
  [5] CFG_SEC_ENA_SEC_CHK — When the ENABLE_SECURE_CHECKING bits in MISC_CTRL_REG and MISC_CTRL_DP_REG on the AHB secure controller are not equal to 10, this bit indicates state 1
  [4] CFG_SEC_ENA_S_PRIV_CHK — When the ENABLE_S_PRIV_CHECK bits in MISC_CTRL_REG and MISC_CTRL_DP_REG on the AHB secure controller are not equal to 10, this bit indicates state 1
  [3] CFG_SEC_ENA_NS_PRIV_CHK — When the ENABLE_NS_PRIV_CHECK bits in MISC_CTRL_REG and MISC_CTRL_DP_REG on the AHB secure controller are not equal to 10, this bit indicates state 1
  [2] CFG_SEC_DIS_VIOL_ABORT — When the DISABLE_VIOLATION_ABORT bits in MISC_CTRL_REG and MISC_CTRL_DP_REG on the AHB secure controller are not equal to 10, this bit indicates state 1
  [1] CFG_SEC_DIS_STRICT_MODE — When CFG_SEC_ENA_SEC_CHK indicates state 0 or when DISABLE_STRICT_MODE bits in MISC_CTRL_REG and MISC_CTRL_DP_REG on the AHB secure controller are equal to 01, this bit indicates state 1
0x9D8 ELS_AS_CFG2 ro reset 0xFFFFFFFF — ELS AS Configuration2
  [31:0] CFG_ELS_CMD_EN — ELS configuration command enable bit
0x9DC ELS_AS_CFG3 ro reset not defined — ELS AS Configuration3
  [31:0] DEVICE_TYPE — Device type identification data
0x9E0 ELS_AS_ST0 ro — ELS AS State Register
  [21:18] ST_GLITCH_DETECT_FLAG — GLITCH_DETECT_FLAG is state of 4-bit Glitch Ripple Counter output.
  [17] ST_IFR_LOAD_FAILED — When IFR load fail flag is state 1, this bit indicates state 1
  [16] ST_XO40M_FAILED — When XO40M oscillation fail flag is state 1, this bit indicates state 1
  [15] ST_XO32K_FAILED — When XO32K oscillation fail flag is state 1, this bit indicates state 1
  [14] ST_ALLOW_TEST_ACCESS — When JTAG TAP access is allowed, this bit indicates state 1.
  [10] ST_DAP_ENABLE_CPU0 — When DAP to AP0 for CPU0 (CM33) debug access is allowed, this bit indicates state 1
  [7] ST_CPU0_SPNIDEN — When CPU0 (CM33) "spniden" input is state 1, this bit indicates state 1
  [6] ST_CPU0_SPIDEN — When CPU0 (CM33) "spiden" input is state 1, this bit indicates state 1
  [5] ST_CPU0_NIDEN — When CPU0 (CM33) "niden" input is state 1, this bit indicates state 1
  [4] ST_CPU0_DBGEN — When CPU0 (CM33) "deben" input is state 1, this bit indicates state 1
  [3:0] ST_TEMPORAL_STATE — TEMPORAL_STATE[3:0] in the ELS_TEMPORAL_STATE register reflects this register
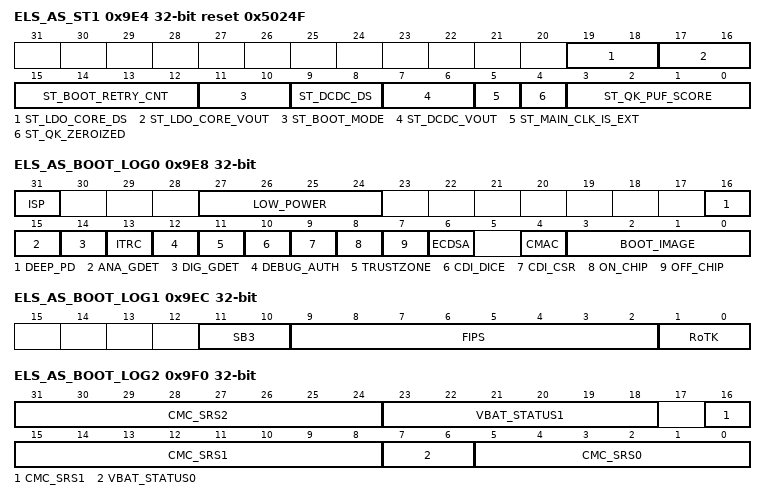
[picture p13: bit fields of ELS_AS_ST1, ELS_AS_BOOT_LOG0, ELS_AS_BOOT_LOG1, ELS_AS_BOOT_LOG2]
0x9E4 ELS_AS_ST1 ro reset 0x5024F — ELS AS State1
  [19:18] ST_LDO_CORE_DS — LDO_CORE drive strength setting. Default is normal drive.
  [17:16] ST_LDO_CORE_VOUT — VOUT[1:0] setting on LDO Core register in SPC block will reflect to this register. Default is 1.0V
  [15:12] ST_BOOT_RETRY_CNT — BOOT_RETRY_CNT[3:0] in the ELS_BOOT_RETRY_CNT register reflects this register
  [11:10] ST_BOOT_MODE — ISP pin status during boot. By default ISP pin is pulled up. If want to enter ISP mode during boot, ISP pin should be pull down when out of reset.
  [9:8] ST_DCDC_DS — DCDC drive strength setting. Default is normal drive.
  [7:6] ST_DCDC_VOUT — VOUT[1:0] setting on DCDC0 register in SPC block will reflect to this register. Default is 1.0V
  [5] ST_MAIN_CLK_IS_EXT — When MAIN_CLK is running from external clock source either XO32M, XO32K or GPIO CLKIN, this bit indicates state 1
  [4] ST_QK_ZEROIZED — This register bit indicates the state of "qk_zeroized" output from QK PUF block
  [3:0] ST_QK_PUF_SCORE — These register bits indicate the state of "qk_puf_score[3:0]" outputs from QK PUF block
0x9E8 ELS_AS_BOOT_LOG0 ro — Boot state captured during boot: Main ROM log
  [31] ISP — ISP pin state at boot time. ROM copies CMC->MR0[0].
  [27:24] LOW_POWER — Last low-power mode value. ROM copies SPC_LP_MODE field from SPC->SC[7:4].
  [16] DEEP_PD — Boot from deep-power down state.
  [15] ANA_GDET — Analog glitch detector is enabled during boot.
  [14] DIG_GDET — Digital glitch detector is enabled during boot.
  [13] ITRC — ITRC zeroize event is handled in this session of boot.
  [12] DEBUG_AUTH — Debug authentication done in this session prior to boot.
  [11] TRUSTZONE — TrustZone preset data is loaded during this boot.
  [10] CDI_DICE — CDI per DICE specification is computed on this boot.
  [9] CDI_CSR — CDI based device keys are derived for CSR harvesting on this boot.
  [8] ON_CHIP — On-chip Prince is enabled during boot.
  [7] OFF_CHIP — Off-chip Prince is enabled during boot.
  [6] ECDSA — ECDSA P-384 verification is done on this boot.
  [4] CMAC — CMAC verify is used instead of ECDSA verify on this boot.
  [3:0] BOOT_IMAGE — Boot image source used during this boot.
    0=Internal flash image 0; 1=Internal flash image 1; 2=FlexSPI flash image 0; 3=FlexSPI flash image 1; 4=Recovery SPI flash image; 5=Serial boot image (write-memory and execute ISP command used); 6=Receive SB3 containing SB_JUMP command is used; 7=Customer SBL/recovery image (Bank1 IFR0); 8=NXP MAD recovery image (Bank1 IFR0); 9=NXP ROM extension (NMPA - Bank0 IFR0)
0x9EC ELS_AS_BOOT_LOG1 ro — Boot state captured during boot: Library log
  [11:10] SB3 — SB3 type (valid after nboot_sb3_load_manifest()).
    0=CUSTOMER (customer fw load/update file.); 1=NXP (NXP Provisioning FW.); 2=OEM (ELS signed OEM Provisioning FW.)
  [9:2] FIPS — FIPS self-test is executed and PASS during this boot. When a bit is set, means self-test is executed and it FAILS. When a bit is clear, means corresponding self-test is executed and PASS or it is not executed.
  [1:0] RoTK — RoTK index used for this boot.
0x9F0 ELS_AS_BOOT_LOG2 ro — Boot state captured during boot: Hardware status signals log
  [31:24] CMC_SRS2 — CMC->SRS[31:24]
  [23:18] VBAT_STATUS1 — VBAT->STATUSA[11:6] | ~VBAT->STATUSB[11:6]
  [16:8] CMC_SRS1 — CMC->SRS[16:8]
  [7:6] VBAT_STATUS0 — VBAT->STATUSA[1:0] | ~VBAT->STATUSB[1:0]
  [5:0] CMC_SRS0 — CMC->SRS[5:0]
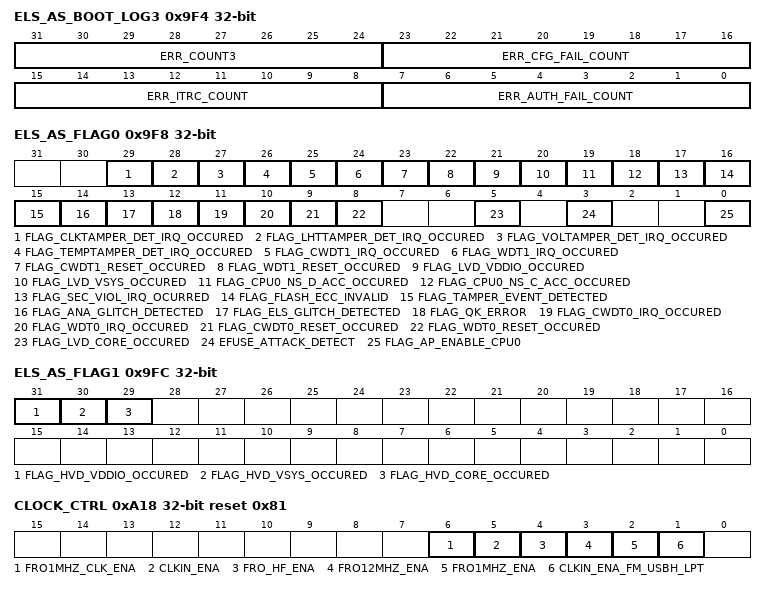
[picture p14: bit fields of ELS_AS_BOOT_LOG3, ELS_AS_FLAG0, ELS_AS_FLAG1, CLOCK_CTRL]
0x9F4 ELS_AS_BOOT_LOG3 ro — Boot state captured during boot: Security log
  [31:24] ERR_COUNT3 — CFPA->ERR_COUNT3[7:0]
  [23:16] ERR_CFG_FAIL_COUNT — CFPA->ERR_CFG_FAIL_COUNT[7:0]
  [15:8] ERR_ITRC_COUNT — CFPA->ERR_ITRC_COUNT[7:0]
  [7:0] ERR_AUTH_FAIL_COUNT — CFPA->ERR_AUTH_FAIL_COUNT[7:0]
0x9F8 ELS_AS_FLAG0 ro
  [all] fields
    0=DISABLE (Not Triggered); 1=ENABLE (Triggered)
  [29] FLAG_CLKTAMPER_DET_IRQ_OCCURED — This flag bit is set as 1 when clock temper IRQ is enabled and IRQ event is triggered. This register is cleared 0 by PMC reset event.
  [28] FLAG_LHTTAMPER_DET_IRQ_OCCURED — This flag bit is set as 1 when light temper IRQ is enabled and IRQ event is triggered. This register is cleared 0 by PMC reset event.
  [27] FLAG_VOLTAMPER_DET_IRQ_OCCURED — This flag bit is set as 1 when voltage temper IRQ is enabled and IRQ event is triggered. This register is cleared 0 by PMC reset event.
  [26] FLAG_TEMPTAMPER_DET_IRQ_OCCURED — This flag bit is set as 1 when temperature temper IRQ is enabled and IRQ event is triggered. This register is cleared 0 by PMC reset event.
  [25] FLAG_CWDT1_IRQ_OCCURED — This flag bit is set as 1 when Code WatchDog Timer 1 IRQ is enabled and IRQ event is triggered. This register is cleared 0 by PMC reset event.
  [24] FLAG_WDT1_IRQ_OCCURED — This flag bit is set as 1 when WatchDog Timer 1 IRQ is enabled and IRQ event is triggered. This register is cleared 0 by PMC reset event.
  [23] FLAG_CWDT1_RESET_OCCURED — This flag bit is set as 1 when Code WatchDog Timer 1 reset is enabled and reset event is triggered. This register is cleared 0 by AO domain POR.
  [22] FLAG_WDT1_RESET_OCCURED — This flag bit is set as 1 when WatchDog Timer 1 reset is enabled and reset event is triggered. This register is cleared 0 by AO domain POR.
  [21] FLAG_LVD_VDDIO_OCCURED — This flag register is set 1 when VDD LVD event is triggered. This register is cleared 0 by PMC reset event.
  [20] FLAG_LVD_VSYS_OCCURED — This flag register is set 1 when VDD_SYS LVD event is triggered. This register is cleared 0 by PMC reset event.
  [19] FLAG_CPU0_NS_D_ACC_OCCURED — This flag bit is set as 1 when CPU0 (CM33) makes non-secure data transactions. This register is cleared 0 by PMC reset event.
  [18] FLAG_CPU0_NS_C_ACC_OCCURED — This flag bit is set as 1 when CPU0 (CM33) makes non-secure code transactions. This register is cleared 0 by PMC reset event.
  [17] FLAG_SEC_VIOL_IRQ_OCURRED — This flag bit is set as 1 when security violation is indicated from FLASH sub-system or AHB bus matrix.
  [16] FLAG_FLASH_ECC_INVALID — This flag bit is set as 1 when FLASH controller indicates ECC error. This register is cleared 0 by PMC reset event.
  [15] FLAG_TAMPER_EVENT_DETECTED — This flag bit is set as 1 when tamper event is flagged from TDET. This register is cleared 0 by AO domain POR or by PMC reset event, if tamper detection event is cleared by software.
  [14] FLAG_ANA_GLITCH_DETECTED — This flag bit is set as 1 when ANALOG GDET error is flagged in SYSCON block. This register is cleared 0 by PMC reset event.
  [13] FLAG_ELS_GLITCH_DETECTED — This flag bit is set as 1 when GDET error is flagged. This register is cleared 0 by PMC reset event.
  [12] FLAG_QK_ERROR — This flag bit is set as 1 when QK_ERROR is flagged from QK PUF block. This register is cleared 0 by PMC reset event.
  [11] FLAG_CWDT0_IRQ_OCCURED — This flag bit is set as 1 when Code WatchDog Timer 0 IRQ is enabled and IRQ event is triggered. This register is cleared 0 by PMC reset event.
  [10] FLAG_WDT0_IRQ_OCCURED — This flag bit is set as 1 when WatchDog Timer 0 IRQ is enabled and IRQ event is triggered. This register is cleared 0 by PMC reset event.
  [9] FLAG_CWDT0_RESET_OCCURED — This flag bit is set as 1 when Code WatchDog Timer 0 reset is enabled and reset event is triggered. This register is cleared 0 by AO domain POR.
  [8] FLAG_WDT0_RESET_OCCURED — This flag bit is set as 1 when WatchDog Timer 0 reset is enabled and reset event is triggered. This register is cleared 0 by AO domain POR.
  [5] FLAG_LVD_CORE_OCCURED — This flag register is set 1 when VDD_CORE LVD event is triggered. This register is cleared 0 by PMC reset event.
  [3] EFUSE_ATTACK_DETECT — OTPC can output attack_detect signal when it detects attack when load shadow registers. The output will be cleared by reset. ELS_AS_FLAG is reset by PoR, so the status can be recorded.
  [0] FLAG_AP_ENABLE_CPU0 — This flag bit is set as 1 when DAP enables AP0 for CPU0 (CM33) debug access. The register is cleared 0 by PMC reset event.
0x9FC ELS_AS_FLAG1 ro
  [all] fields
    0=DISABLE (Not Triggered); 1=ENABLE (Triggered)
  [31] FLAG_HVD_VDDIO_OCCURED — This flag bit is set as 1 when HVD from VDD power domain is triggered
  [30] FLAG_HVD_VSYS_OCCURED — This flag bit is set as 1 when HVD from VDD_SYS power domain is triggered
  [29] FLAG_HVD_CORE_OCCURED — This flag bit is set as 1 when HVD from VDD_CORE power domain is triggered.
0xA18 CLOCK_CTRL reset 0x81 — Clock Control
  [all] fields
    0=DISABLE (Clock is not enabled); 1=ENABLE (Clock is enabled)
  [6] FRO1MHZ_CLK_ENA — Enables FRO_1MHz clock for clock muxing in clock gen
  [5] CLKIN_ENA — Enables clk_in clock for MICFIL, CAN0/1, I3C0/1, SAI0/1, clkout.
  [4] FRO_HF_ENA — Enables FRO HF clock for the Frequency Measure module
  [3] FRO12MHZ_ENA — Enables the FRO_12MHz clock for the Flash, LPTMR0/1, and Frequency Measurement modules
  [2] FRO1MHZ_ENA — Enables the FRO_1MHz clock for RTC module and for UTICK
  [1] CLKIN_ENA_FM_USBH_LPT — Enables the clk_in clock for the Frequency Measurement, USB HS and LPTMR0/1 modules.
0xB30 I3C1FCLKSEL reset 0x7 — I3C1 Functional Clock Selection
  [2:0] SEL — I3C1 clock select
    values as I3C0FCLKSEL.SEL
0xB40 I3C1FCLKDIV reset 0x40000000 — I3C1 Functional Clock FCLK Divider
  fields as TRACECLKDIV
0xB60 GRAY_CODE_LSB — Gray to Binary Converter Gray code_gray[31:0]
  [31:0] code_gray_31_0 — Gray code [31:0]
0xB64 GRAY_CODE_MSB — Gray to Binary Converter Gray code_gray[41:32]
  [9:0] code_gray_41_32 — Gray code [41:32]
0xB68 BINARY_CODE_LSB ro — Gray to Binary Converter Binary Code [31:0]
  [31:0] code_bin_31_0 — Binary code [31:0]
0xB6C BINARY_CODE_MSB ro — Gray to Binary Converter Binary Code [41:32]
  [9:0] code_bin_41_32 — Binary code [41:32]
0xE04 AUTOCLKGATEOVERRIDE reset 0xFFFF — Control Automatic Clock Gating
  [all] fields
    0=DISABLE (Automatic clock gating is not overridden); 1=ENABLE (Automatic clock gating is overridden (Automatic clock gating is disabled).)
  [5] RAME_CTRL — Controls automatic clock gating for the RAMD Controller.
  [4] RAMD_CTRL — Controls automatic clock gating for the RAMD Controller
  [3] RAMC_CTRL — Controls automatic clock gating for the RAMC Controller
  [2] RAMB_CTRL — Controls automatic clock gating for the RAMB Controller
0xE2C AUTOCLKGATEOVERRIDEC — Control Automatic Clock Gating C
  [31] RAMA — Controls automatic clock gating of the RAMA controller
    values as the fields of AUTOCLKGATEOVERRIDE
  [30] RAMX — Controls automatic clock gating of the RAMX controller
    values as the fields of AUTOCLKGATEOVERRIDE
0xE38 PWM0SUBCTL — PWM0 Submodule Control
  [n+12] DMAVALM{n} (n=0..3) — PWM0 submodule {n} DMA compare value done mask
  [n] CLK{n}_EN (n=0..3) — Enables PWM0 SUB Clock{n}
0xE3C PWM1SUBCTL — PWM1 Submodule Control
  [n+12] DMAVALM{n} (n=0..3) — PWM1 submodule {n} DMA compare value done mask
  [n] CLK{n}_EN (n=0..3) — Enables PWM1 SUB Clock{n}
0xE40 CTIMERGLOBALSTARTEN — CTIMER Global Start Enable
  [all] fields
    0=DISABLE; 1=ENABLE
  [n] CTIMER{n}_CLK_EN (n=0..4) — Enables the CTIMER{n} function clock
0xE44 ECC_ENABLE_CTRL reset 0x3 — RAM ECC Enable Control
  [all] fields
    0=DISABLE (ECC is disabled); 1=ENABLE (ECC is enabled)
  [2] RAMD_RAMC_ECC_ENABLE — RAMD and RAMC ECC enable
  [1] RAMB_RAMX_ECC_ENABLE — RAMB and RAMX ECC enable
  [0] RAMA_ECC_ENABLE
0xFA0 DEBUG_LOCK_EN reset 0x5 — Control Write Access to Security
  [3:0] LOCK_ALL — Controls write access to the security registers
    0=DISABLE (Any other value than b1010: disables write access to all registers); 10=ENABLE (Enables write access to all registers)
0xFA4 DEBUG_FEATURES reset 0x1555 — Cortex Debug Features Control
  [all] fields
    1=DISABLE (Disables debug); 2=ENABLE (Enables debug)
  [7:6] CPU0_SPNIDEN — CPU0 secure privileged non-invasive debug control
  [5:4] CPU0_SPIDEN — CPU0 secure privileged invasive debug control
  [3:2] CPU0_NIDEN — CPU0 non-invasive debug control
  [1:0] CPU0_DBGEN — CPU0 invasive debug control
0xFA8 DEBUG_FEATURES_DP reset 0x1555 — Cortex Debug Features Control (Duplicate)
  fields as DEBUG_FEATURES
0xFB4 SWD_ACCESS_CPU0 — CPU0 Software Debug Access
  [31:0] SEC_CODE — CPU0 SWD-AP: 0x12345678
    0=DISABLE (CPU0 DAP is not allowed. Reading back register is read as 0x5.); 0x12345678=ENABLE (Value to write to enable CPU0 SWD access. Reading back register is read as 0xA.)
0xFC0 DEBUG_AUTH_BEACON — Debug Authentication BEACON
  [31:0] BEACON — Sets by the debug authentication code in ROM to pass the debug beacons (Credential Beacon and Authentication Beacon) to the application code.
0xFF0 JTAG_ID ro reset 0x726402B (reset mask 0xFFFFFFF) — JTAG Chip ID
  [31:0] JTAG_ID — Indicates the device ID
0xFF4 DEVICE_TYPE ro reset not defined
  [31:0] DEVICE_TYPE — Indicates DEVICE TYPE.
0xFF8 DEVICE_ID0 ro (reset mask 0xF00FFF00) — Device ID
  [23:20] ROM_REV_MINOR — ROM revision.
0xFFC DIEID ro reset 0x5209A0 (reset mask 0xFFFFF0) — Chip Revision ID and Number
  [27:8] MCO_NUM_IN_DIE_ID — Chip number
  [7:4] MAJOR_REVISION — Chip major revision
  [3:0] MINOR_REVISION — Chip minor revision

## Notices in the file
Copyright 2016-2023 NXP
SPDX-License-Identifier: BSD-3-Clause
